AUTOSAR XML (schema 4-0-3)
standard types defined: Boolean, UInt16, UInt32, UInt8
package /AUTOSAR_Platform/DataConstrs
  range DC_Boolean: raw 0..1
  range DC_UInt16: raw 0..65535
  range DC_UInt8: raw 0..255
package /PATAC/MSM/ComponentTypes
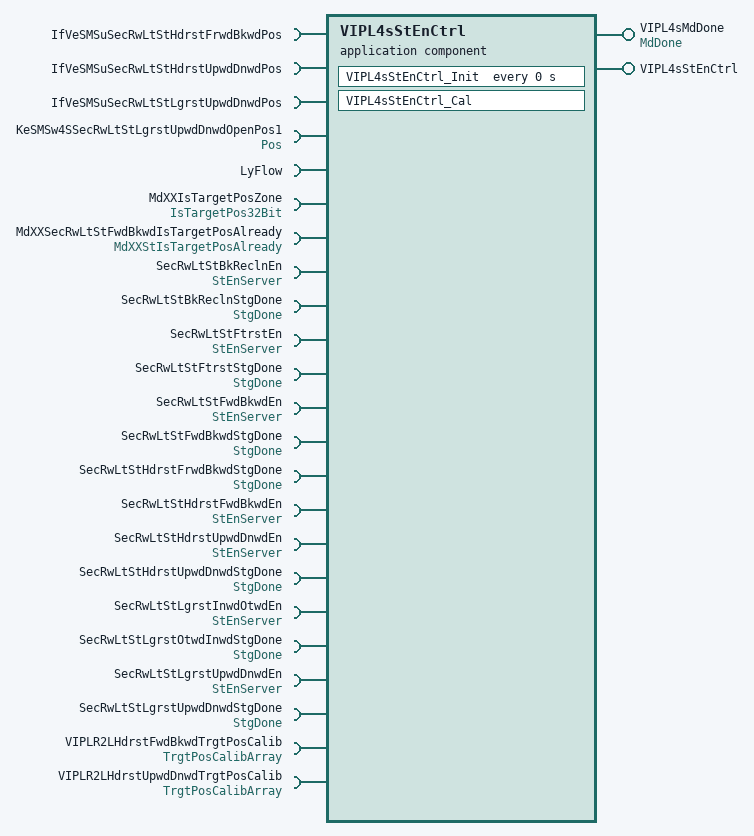
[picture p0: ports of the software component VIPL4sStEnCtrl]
  application sw component type VIPL4sStEnCtrl
    provide port VIPL4sMdDone: nonqueued-sender-com-spec{data-element=MdDone/Val, init-value=0}, provided-interface=MdDone
    provide port VIPL4sStEnCtrl: server-com-spec{operation=VIPL4sStEnCtrl/Cal, queue-length=1}, provided-interface=VIPL4sStEnCtrl
    23 x require port:
      IfVeSMSuSecRwLtStHdrstFrwdBkwdPos: nonqueued-receiver-com-spec{data-element=IfVeSMSuSecRwLtStHdrstFrwdBkwdPos/Val, filter=data-filter-type=ALWAYS, init-value=0}, required-interface=IfVeSMSuSecRwLtStHdrstFrwdBkwdPos
      IfVeSMSuSecRwLtStHdrstUpwdDnwdPos: nonqueued-receiver-com-spec{data-element=IfVeSMSuSecRwLtStHdrstUpwdDnwdPos/Val, filter=data-filter-type=ALWAYS, init-value=0}, required-interface=IfVeSMSuSecRwLtStHdrstUpwdDnwdPos
      IfVeSMSuSecRwLtStLgrstUpwdDnwdPos: nonqueued-receiver-com-spec{data-element=IfVeSMSuSecRwLtStLgrstUpwdDnwdPos/Val, filter=data-filter-type=ALWAYS, init-value=0}, required-interface=IfVeSMSuSecRwLtStLgrstUpwdDnwdPos
      KeSMSw4SSecRwLtStLgrstUpwdDnwdOpenPos1: parameter-require-com-spec{init-value=0, parameter=Val}, required-interface=Pos
      LyFlow: client-com-spec=LyFlow/Cal, required-interface=LyFlow
      MdXXIsTargetPosZone: nonqueued-receiver-com-spec{data-element=IsTargetPos32Bit/Val, filter=data-filter-type=ALWAYS, init-value=0}, required-interface=IsTargetPos32Bit
      MdXXSecRwLtStFwdBkwdIsTargetPosAlready: nonqueued-receiver-com-spec{data-element=MdXXStIsTargetPosAlready/Val, filter=data-filter-type=ALWAYS, init-value=0}, required-interface=MdXXStIsTargetPosAlready
      SecRwLtStBkReclnEn: required-com-specs=[Clear, Get, Set], required-interface=StEnServer
      SecRwLtStBkReclnStgDone: nonqueued-receiver-com-spec{data-element=StgDone/Val, filter=data-filter-type=ALWAYS, init-value=0}, required-interface=StgDone
      SecRwLtStFtrstEn: required-com-specs=[Clear, Get, Set], required-interface=StEnServer
      SecRwLtStFtrstStgDone: nonqueued-receiver-com-spec{data-element=StgDone/Val, filter=data-filter-type=ALWAYS, init-value=0}, required-interface=StgDone
      SecRwLtStFwdBkwdEn: required-com-specs=[Clear, Get, Set], required-interface=StEnServer
      SecRwLtStFwdBkwdStgDone: nonqueued-receiver-com-spec{data-element=StgDone/Val, filter=data-filter-type=ALWAYS, init-value=0}, required-interface=StgDone
      SecRwLtStHdrstFrwdBkwdStgDone: nonqueued-receiver-com-spec{data-element=StgDone/Val, filter=data-filter-type=ALWAYS, init-value=0}, required-interface=StgDone
      SecRwLtStHdrstFwdBkwdEn: required-com-specs=[Clear, Get, Set], required-interface=StEnServer
      SecRwLtStHdrstUpwdDnwdEn: required-com-specs=[Clear, Get, Set], required-interface=StEnServer
      SecRwLtStHdrstUpwdDnwdStgDone: nonqueued-receiver-com-spec{data-element=StgDone/Val, filter=data-filter-type=ALWAYS, init-value=0}, required-interface=StgDone
      SecRwLtStLgrstInwdOtwdEn: required-com-specs=[Clear, Get, Set], required-interface=StEnServer
      SecRwLtStLgrstOtwdInwdStgDone: nonqueued-receiver-com-spec{data-element=StgDone/Val, filter=data-filter-type=ALWAYS, init-value=0}, required-interface=StgDone
      SecRwLtStLgrstUpwdDnwdEn: required-com-specs=[Clear, Get, Set], required-interface=StEnServer
      SecRwLtStLgrstUpwdDnwdStgDone: nonqueued-receiver-com-spec{data-element=StgDone/Val, filter=data-filter-type=ALWAYS, init-value=0}, required-interface=StgDone
      VIPLR2LHdrstFwdBkwdTrgtPosCalib: nonqueued-receiver-com-spec{data-element=TrgtPosArray, filter=data-filter-type=ALWAYS, init-value=[4095, 4095, 4095]}, required-interface=TrgtPosCalibArray
      VIPLR2LHdrstUpwdDnwdTrgtPosCalib: nonqueued-receiver-com-spec{data-element=TrgtPosArray, filter=data-filter-type=ALWAYS, init-value=[4095, 4095, 4095]}, required-interface=TrgtPosCalibArray
    behavior VIPL4sStEnCtrl_InternalBehavior
      operation invoked event OIT_VIPL4sStEnCtrl_Cal_VIPL4sStEnCtrl_Cal: start-on-event=VIPL4sStEnCtrl_Cal, operation=VIPL4sStEnCtrl.Cal
      timing event VIPL4sStEnCtrl_InitEvent: start-on-event=VIPL4sStEnCtrl_Init, period=0
      runnable VIPL4sStEnCtrl_Cal
        data-receive-point-by-arguments:
          14 x access:
            REC_IfVeSMSuSecRwLtStHdrstFrwdBkwdPos_Val: accessed-variable=IfVeSMSuSecRwLtStHdrstFrwdBkwdPos.Val
            REC_IfVeSMSuSecRwLtStHdrstUpwdDnwdPos_Val: accessed-variable=IfVeSMSuSecRwLtStHdrstUpwdDnwdPos.Val
            REC_IfVeSMSuSecRwLtStLgrstUpwdDnwdPos_Val: accessed-variable=IfVeSMSuSecRwLtStLgrstUpwdDnwdPos.Val
            REC_MdXXIsTargetPosZone_Val: accessed-variable=MdXXIsTargetPosZone.Val
            REC_MdXXSecRwLtStFwdBkwdIsTargetPosAlready_Val: accessed-variable=MdXXSecRwLtStFwdBkwdIsTargetPosAlready.Val
            REC_SecRwLtStBkReclnStgDone_Val: accessed-variable=SecRwLtStBkReclnStgDone.Val
            REC_SecRwLtStFtrstStgDone_Val: accessed-variable=SecRwLtStFtrstStgDone.Val
            REC_SecRwLtStFwdBkwdStgDone_Val: accessed-variable=SecRwLtStFwdBkwdStgDone.Val
            REC_SecRwLtStHdrstFrwdBkwdStgDone_Val: accessed-variable=SecRwLtStHdrstFrwdBkwdStgDone.Val
            REC_SecRwLtStHdrstUpwdDnwdStgDone_Val: accessed-variable=SecRwLtStHdrstUpwdDnwdStgDone.Val
            REC_SecRwLtStLgrstOtwdInwdStgDone_Val: accessed-variable=SecRwLtStLgrstOtwdInwdStgDone.Val
            REC_SecRwLtStLgrstUpwdDnwdStgDone_Val: accessed-variable=SecRwLtStLgrstUpwdDnwdStgDone.Val
            REC_VIPLR2LHdrstFwdBkwdTrgtPosCalib_TrgtPosArray: accessed-variable=VIPLR2LHdrstFwdBkwdTrgtPosCalib.TrgtPosArray
            REC_VIPLR2LHdrstUpwdDnwdTrgtPosCalib_TrgtPosArray: accessed-variable=VIPLR2LHdrstUpwdDnwdTrgtPosCalib.TrgtPosArray
        data-send-points:
          access SEND_VIPLMdDone_Val: accessed-variable=VIPL4sMdDone.Val
        parameter access PA_KeSMSw4SSecRwLtStLgrstUpwdDnwdOpenPos1_Val: accessed-parameter=KeSMSw4SSecRwLtStLgrstUpwdDnwdOpenPos1.Val
        15 x sync call, all with timeout=0:
          SC_LyFlow_Cal: operation=LyFlow.Cal
          SC_SecRwLtStBkReclnEn_Clear: operation=SecRwLtStBkReclnEn.Clear
          SC_SecRwLtStBkReclnEn_Set: operation=SecRwLtStBkReclnEn.Set
          SC_SecRwLtStFtrstEn_Clear: operation=SecRwLtStFtrstEn.Clear
          SC_SecRwLtStFtrstEn_Set: operation=SecRwLtStFtrstEn.Set
          SC_SecRwLtStFwdBkwdEn_Clear: operation=SecRwLtStFwdBkwdEn.Clear
          SC_SecRwLtStFwdBkwdEn_Set: operation=SecRwLtStFwdBkwdEn.Set
          SC_SecRwLtStHdrstFwdBkwdEn_Clear: operation=SecRwLtStHdrstFwdBkwdEn.Clear
          SC_SecRwLtStHdrstFwdBkwdEn_Set: operation=SecRwLtStHdrstFwdBkwdEn.Set
          SC_SecRwLtStHdrstUpwdDnwdEn_Clear: operation=SecRwLtStHdrstUpwdDnwdEn.Clear
          SC_SecRwLtStHdrstUpwdDnwdEn_Set: operation=SecRwLtStHdrstUpwdDnwdEn.Set
          SC_SecRwLtStLgrstInwdOtwdEn_Clear: operation=SecRwLtStLgrstInwdOtwdEn.Clear
          SC_SecRwLtStLgrstInwdOtwdEn_Set: operation=SecRwLtStLgrstInwdOtwdEn.Set
          SC_SecRwLtStLgrstUpwdDnwdEn_Clear: operation=SecRwLtStLgrstUpwdDnwdEn.Clear
          SC_SecRwLtStLgrstUpwdDnwdEn_Set: operation=SecRwLtStLgrstUpwdDnwdEn.Set
      runnable VIPL4sStEnCtrl_Init
        parameter access PA_KeSMSw4SSecRwLtStLgrstUpwdDnwdOpenPos1_Val: accessed-parameter=KeSMSw4SSecRwLtStLgrstUpwdDnwdOpenPos1.Val
  swc implementation VIPL4sStEnCtrl_Implementation: behavior=VIPL4sStEnCtrl_InternalBehavior
    code-descriptors:
      code Default: artifact-descriptors=autosar-engineering-object={short-label=Default, category=SWSRC}
package /PATAC/MSM/ModeAdjust/CalPortInterface
  parameter interface Pos
    parameter data prototype Val: sw-calibration-access=READ-WRITE, type=UInt16
package /PATAC/MSM/ModeAdjust/DataType
  impl type TrgtPosCalibArray: category=ARRAY, sw-calibration-access=READ-ONLY, type-emitter=RTE  # 0:pos 1:max 2:min
    element Element: array-size=3, array-size-semantics=FIXED-SIZE, implementation-data-type=UInt16, invalid-value=0
package /PATAC/MSM/ModeAdjust/PortInterface
  client server interface LyFlow
    operation Cal
      20 x arg, all with server-argument-impl-policy=USE-ARGUMENT-TYPE:
        BkReclnStgDone: type=Boolean, direction=IN
        LgrstUpwdDnwdPos: type=UInt16, direction=IN
        LgrstUpwdDnwdOpenPos1: type=UInt16, direction=IN
        LgrstUpwdStgDone: type=Boolean, direction=IN
        FtrstStgDone: type=Boolean, direction=IN
        LgrstInwdStgDone: type=Boolean, direction=IN
        Chkhdflg: type=Boolean, direction=IN
        HdrstUpwdDnwdStgDone: type=Boolean, direction=IN
        HdrstFrwdBkwdStgDone: type=Boolean, direction=IN
        FwdBkwdStgDone: type=Boolean, direction=IN
        FwdBkwdIsPosAlready: type=Boolean, direction=IN
        Failflg: type=Boolean, direction=OUT
        BkReclnEn: type=Boolean, direction=OUT
        HdrstUpwdEn: type=Boolean, direction=OUT
        HdrstFrwdEn: type=Boolean, direction=OUT
        LgrstUpwdDnwdEn: type=Boolean, direction=OUT
        FtrstEn: type=Boolean, direction=OUT
        LgrstInwdOtwdEn: type=Boolean, direction=OUT
        FwdBkwdEn: type=Boolean, direction=OUT
        FailBkwd: type=Boolean, direction=OUT
  client server interface StEnServer
    operation Clear
      arg data: type=UInt8, direction=IN, server-argument-impl-policy=USE-ARGUMENT-TYPE
    operation Get
      arg data: type=UInt32, direction=OUT, server-argument-impl-policy=USE-ARGUMENT-TYPE
    operation Set
      arg data: type=UInt8, direction=IN, server-argument-impl-policy=USE-ARGUMENT-TYPE
  client server interface VIPL4sStEnCtrl
    operation Cal
  5 x sender receiver interface:
    IsTargetPos32Bit: invalidation-policy{data-element=IsTargetPos32Bit/Val, handle-invalid=DONT-INVALIDATE}
      data Val: type=UInt32
    MdDone: invalidation-policy{data-element=MdDone/Val, handle-invalid=DONT-INVALIDATE}
      data Val: type=UInt8
    MdXXStIsTargetPosAlready: invalidation-policy{data-element=MdXXStIsTargetPosAlready/Val, handle-invalid=DONT-INVALIDATE}
      data Val: type=UInt32
    StgDone: invalidation-policy{data-element=StgDone/Val, handle-invalid=DONT-INVALIDATE}
      data Val: type=Boolean
    TrgtPosCalibArray: invalidation-policy{data-element=TrgtPosArray, handle-invalid=DONT-INVALIDATE}
      data TrgtPosArray: type=TrgtPosCalibArray  # 0:Pos 1:Max 2:Min
package /PATAC/MSM/PortInterfaces
  sender receiver interface IfVeSMSuSecRwLtStHdrstFrwdBkwdPos: invalidation-policy{data-element=IfVeSMSuSecRwLtStHdrstFrwdBkwdPos/Val, handle-invalid=DONT-INVALIDATE}
    data Val: type=UInt16
  sender receiver interface IfVeSMSuSecRwLtStHdrstUpwdDnwdPos: invalidation-policy{data-element=IfVeSMSuSecRwLtStHdrstUpwdDnwdPos/Val, handle-invalid=DONT-INVALIDATE}
    data Val: type=UInt16
  sender receiver interface IfVeSMSuSecRwLtStLgrstUpwdDnwdPos: invalidation-policy{data-element=IfVeSMSuSecRwLtStLgrstUpwdDnwdPos/Val, handle-invalid=DONT-INVALIDATE}
    data Val: type=UInt16
